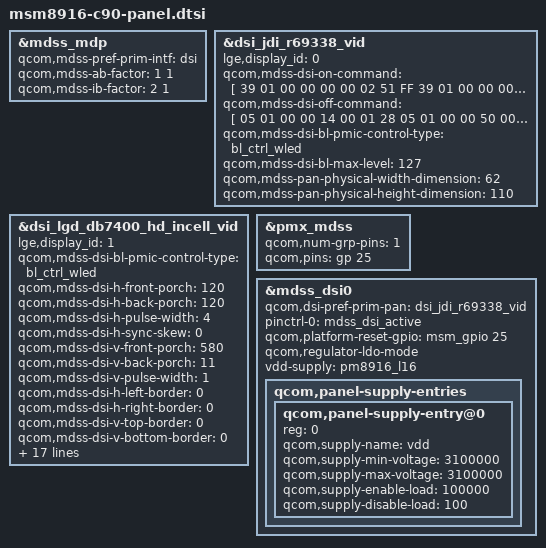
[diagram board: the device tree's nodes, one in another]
/* Copyright (c) 2013, Code Aurora Forum. All rights reserved.
 *
 * This program is free software; you can redistribute it and/or modify
 * it under the terms of the GNU General Public License version 2 and
 * only version 2 as published by the Free Software Foundation.
 *
 * This program is distributed in the hope that it will be useful,
 * but WITHOUT ANY WARRANTY; without even the implied warranty of
 * MERCHANTABILITY or FITNESS FOR A PARTICULAR PURPOSE.  See the
 * GNU General Public License for more details.
 */

#include "../msm8916-lge-common/dsi-panel-jdi-hd-video.dtsi"
#include "../msm8916-lge-common/dsi-panel-lgd-db7400-720p-video.dtsi"

&mdss_mdp {
       qcom,mdss-pref-prim-intf = "dsi";
       qcom,mdss-ab-factor = <1 1>;
       qcom,mdss-ib-factor = <2 1>;
};

&dsi_jdi_r69338_vid {
	   lge,display_id = <0>;
	   qcom,mdss-dsi-on-command = [
		   39 01 00 00 00 00 02
		   51 FF

		   39 01 00 00 00 00 02
		   53 0C			//BCTRL Off (2c => 0c)

		   39 01 00 00 00 00 02
		   55 00			//SRE Off (40 => 00)

		   29 01 00 00 00 00 02
		   B0 04

		   29 01 00 00 00 00 08
		   B3 14 1A 00 00 00 00
		   00

		   29 01 00 00 00 00 02
		   B4 0C

		   29 01 00 00 00 00 03
		   B6 3A B3

		   29 01 00 00 00 00 2D
		   C1 84 61 10 52 4A 59
		   94 20 03 1C D9 D8 82
		   CF B9 07 17 6B D1 80
		   41 82 94 52 4A 09 10
		   10 10 10 A0 40 42 20
		   12 10 22 00 15 00 01
		   00 00 00

		   29 01 00 00 00 00 0A
		   C2 31 F5 00 00 04 00
		   08 00 00

		   29 01 00 00 00 00 10
		   C4 70 00 00 00 00 22
		   00 00 00 00 06 16 16
		   16 01

		   29 01 00 00 00 00 15
		   C6 54 10 10 04 49 01
		   01 01 01 01 01 45 0D
		   01 01 01 01 06 13 03

		   29 01 00 00 00 00 0D
		   CB F0 F7 FF 3F 30 00
		   00 00 00 00 3C CF

		   29 01 00 00 00 00 02
		   CC 0D

		   29 01 00 00 00 00 06
		   D0 10 91 BB 12 8E

		   29 01 00 00 00 00 06
		   D1 25 00 19 61 06

		   29 01 00 00 00 00 1C
		   D3 0B 37 9F BD B7 33
		   33 17 00 01 00 A0 D8
		   A0 0D 23 23 33 3B F7
		   72 07 3D BF 99 21 FA

		   29 01 00 00 00 00 0C
		   D5 06 00 00 01 28 01
		   28 00 00 00 00

		   29 01 00 00 00 00 0D
		   D9 8A 23 AA AA 0A E4
		   00 06 07 00 00 00

		   29 01 00 00 00 00 31
		   EC 29 00 2C 2B 01 00
		   00 00 00 00 00 00 00
		   00 00 00 07 09 00 11
		   0F 00 00 00 00 50 06
		   00 00 00 00 05 FC 00
		   00 00 03 40 02 13 02
		   02 01 00 00 00 00 00

		   29 01 00 00 00 00 20
		   ED 3B 02 02 03 21 11
		   00 93 00 00 00 00 00
		   03 1E 21 00 DF 00 DD
		   06 F3 3F 00 00 15 00
		   00 00 00 00

		   29 01 00 00 00 00 20
		   EE 1D 02 02 03 00 10
		   00 02 00 00 00 00 00
		   03 00 00 01 C5 01 C4
		   0E 28 23 00 00 2A 00
		   00 00 00 00

		   29 01 00 00 00 00 3F
		   EF 3B 02 02 03 21 11
		   00 93 00 00 00 00 00
		   03 1E 21 00 DF 00 DD
		   06 F3 3F 00 00 15 00
		   00 00 00 00 3B 02 02
		   03 21 11 00 93 00 F0
		   00 00 54 00 03 1E 21
		   00 DF 00 DD 06 F3 3F
		   00 15 00 00 00 00 00

		   29 01 00 00 00 00 1F /* gamma setting 1 */
		   C7 00 0A 16 20 2C 39
		   43 52 36 3E 4B 58 5A
		   5F 67 00 0A 16 20 2C
		   39 43 52 36 3E 4B 58
		   5A 5F 67

		   29 01 00 00 00 00 14 /* gamma setting 2 */
		   C8 00 00 00 00 00 FC
		   00 00 00 00 00 FC 00
		   00 00 00 00 FC 00

		   29 01 00 00 00 00 21 /* Color Enhancement */
		   CA 01 70 9A 95 A2 98
		   95 8F 3F 3F 80 80 08
		   80 08 3F 08 90 0C 0C
		   0A 06 04 04 00 C8 10
		   10 3F 3F 3F 3F

		   29 01 00 00 00 00 02
		   D6 01

		   15 01 00 00 00 00 02
		   36 00

		   05 01 00 00 00 00 01
		   29

		   05 01 00 00 78 00 01
		   11

		   ];

	   qcom,mdss-dsi-off-command = [
		   05 01 00 00 14 00 01
		   28
		   05 01 00 00 50 00 01
		   10
		   ];

	   qcom,mdss-dsi-bl-pmic-control-type = "bl_ctrl_wled";
	   qcom,mdss-dsi-bl-max-level = <127>;
	   qcom,mdss-pan-physical-width-dimension = <62>;
	   qcom,mdss-pan-physical-height-dimension = <110>;
};
&dsi_lgd_db7400_hd_incell_vid {
		lge,display_id = <1>;
		qcom,mdss-dsi-bl-pmic-control-type = "bl_ctrl_wled";
		qcom,mdss-dsi-h-front-porch = <120>;//<40>;//<84>;
		qcom,mdss-dsi-h-back-porch = <120>;//<80>;//<70>;//<88>;
		qcom,mdss-dsi-h-pulse-width = <4>;
		qcom,mdss-dsi-h-sync-skew = <0>;
		qcom,mdss-dsi-v-front-porch = <580>;//<550>;//<400>;//<7>;
		qcom,mdss-dsi-v-back-porch = <11>;//<417>;
		qcom,mdss-dsi-v-pulse-width = <1>;//<4>;
		qcom,mdss-dsi-h-left-border = <0>;
		qcom,mdss-dsi-h-right-border = <0>;
		qcom,mdss-dsi-v-top-border = <0>;
		qcom,mdss-dsi-v-bottom-border = <0>;
		qcom,mdss-pan-physical-width-dimension = < 62 >; //62.1mm
		qcom,mdss-pan-physical-height-dimension = < 110 >; //110.4 mm
		qcom,mdss-dsi-underflow-color = <0>;
		qcom,mdss-dsi-on-command = [
			15 01 00 00 00 00 02    //Set Address Mode
			36 00

			15 01 00 00 00 00 02    //Manufacturer Command Access Protect
			B0 00

			29 01 00 00 00 00 03    //RGB Interface Set
			B1 00 46

			29 01 00 00 00 00 07    //Module Characteristics Set
			B2 50 00 0C 00 00 00
			
			29 01 00 00 00 00 05    //Internal Timing Set
			B3 4F 80 0A 28

			29 01 00 00 00 00 07    //Channel Control
			B4 05 0C 1F 40 11 00
			
			29 01 00 00 00 00 34    //GIP Control Set
			B5 19 04 1C 22 2F 80
			2F 1F 04 40 05 00 20
			09 04 40 05 00 A5 0D
			2F 2F 3F FF 3F FF 01
			7C 00 02 50 23 40 15
			6C CB BA A9 97 8D 1F
			23 40 15 6C CB BA A9
			97 8D 1F

			29 01 00 00 00 00 03    //Touch Enable
			B6 01 01

			29 01 00 00 00 00 04    //GVDDP Control
			B7 00 3A 3B

			29 01 00 00 00 00 10    //VGHL Control
			BB 00 9A 94 30 30 00
			00 00 00 00 00 00 00
			00 13

			29 01 00 00 00 00 03    //Bias Control
			BD 03 33

			15 01 00 00 00 00 02    //VCI1 Control
			BE 03

			29 01 00 00 00 00 07    //Write DSI Control
			95 00 08 10 00 00 00
			
			29 01 00 00 00 00 02    //Touch Control  Set
			CF 07

			29 01 00 00 00 00 03    //Mipi Parameter Setting
			C6 0A 00

			29 01 00 00 00 00 1B    //Touch GIP Control
			D7 01 13 FF 39 0B 04
			14 F4 01 00 00 00 00
			40 01 57 57 2F 28 28
			4B 00 00 00 00 00

			29 01 00 00 00 00 24    //Power Sequence Control
			F0 18 00 00 14 00 00
			00 01 00 03 2B 01 02
			53 58 5D 62 A6 AB B0
			B0 B0 AF B0 AD 85 B0
			B0 5D 58 53 4E 0A 05
			00

			29 01 00 00 00 00 0A    //Positive Gamma Curve for Red
			D0 02 76 32 41 06 00
			33 26 02

			29 01 00 00 00 00 0A    //Negative Gamma Curve for Red
			D1 02 76 32 41 0E 00
			33 26 02

			29 01 00 00 00 00 0A    //Positive Gamma Curve for Green
			D2 02 76 32 41 06 00
			33 26 02

			29 01 00 00 00 00 0A    //Negative Gamma Curve for Green
			D3 02 76 32 41 0E 00
			33 26 02

			29 01 00 00 00 00 0A    //Positive Gamma Curve for Blue
			D4 02 76 32 41 06 00
			33 26 02

			29 01 00 00 00 00 0A    //Negative Gamma Curve for Blue
			D5 02 76 32 41 0E 00
			33 26 02

			29 01 00 00 00 00 02    //VDD1 Setting
			F6 06

			29 01 00 00 00 00 1A /*Preferred Color Compensation*/
			85 1F 6E 22 5A 19 44
			28 7F 4D AD 85 6A 96
			9B 8C 65 51 97 60 B0
			9C 65 51 A5 62

			05 01 00 00 50 00 01    //Sleep out
			11 

			05 01 00 00 00 00 01    //Display on
			29 
			
		];
		qcom,mdss-dsi-off-command1 = [
			05 01 00 00 19 00 01	//Display Off
			28
			05 01 00 00 00 00 01    //Sleep In
			10
		];
		qcom,mdss-dsi-off-command2 = [
			29 01 00 00 00 00 1C	//34->1C GIP Control Set
			B5 19 04 1C 22 2F 80
			2F 1F 04 40 05 00 20
			09 04 40 05 00 A5 0D
			2F 1F 04 00 04 00 00
		//			7C 00 02 50 23 40 15
		//			6C CB BA A9 97 8D 1F
		//			23 40 15 6C CB BA A9
		//			97 8D 1F

			29 01 00 00 00 00 06    //Touch LFD Control Set
			F5 00 06 00 00 C0

			29 01 00 00 14 00 03    //To setting MIPI  Lane  floating
			C8 01 00
		];
		qcom,mdss-dsi-on-command-state = "dsi_lp_mode";
		qcom,mdss-dsi-off-command-state = "dsi_hs_mode";
		qcom,mdss-dsi-panel-timings = [B5 28 1A 00 52 56 20 2E 24 03 04 00];//HFP 120, T_HS_RQST : 21 ->24, HS Trail time : 2C -> 2E
		qcom,mdss-dsi-t-clk-post = <0x03>;
		qcom,mdss-dsi-t-clk-pre = <0x23>;

		qcom,mdss-dsi-bl-min-level = <1>;
		qcom,mdss-dsi-bl-max-level = <127>;
};


&pmx_mdss {
       qcom,num-grp-pins = <1>;
       qcom,pins = <&gp 25>;
};

&mdss_dsi0 {
       qcom,dsi-pref-prim-pan = <&dsi_jdi_r69338_vid>;
       pinctrl-names = "mdss_default";
       pinctrl-0 = <&mdss_dsi_active>;

       qcom,platform-reset-gpio = <&msm_gpio 25 0>;
	   qcom,regulator-ldo-mode;
	   vdd-supply = <&pm8916_l16>;
	   qcom,panel-supply-entries {
        qcom,panel-supply-entry@0 {
            reg = <0>;
            qcom,supply-name = "vdd";
            qcom,supply-min-voltage = <3100000>;
            qcom,supply-max-voltage = <3100000>;
            qcom,supply-enable-load = <100000>;
            qcom,supply-disable-load = <100>;
        };
    };
};

